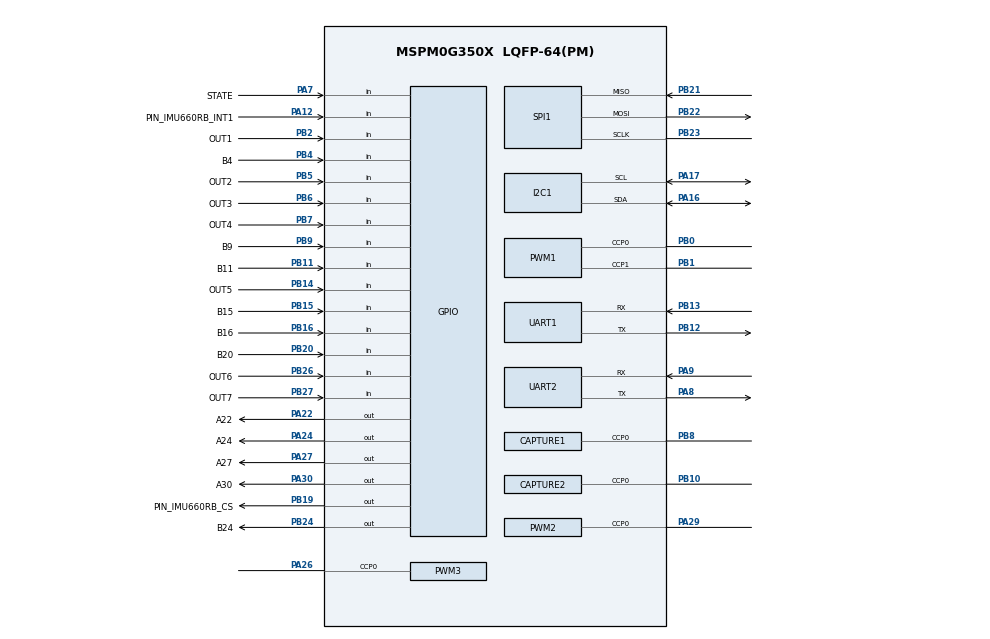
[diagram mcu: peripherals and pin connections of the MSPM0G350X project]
/**
 * @cliArgs --device "MSPM0G350X" --part "Default" --package "LQFP-64(PM)" --product "mspm0_sdk@2.05.01.00"
 * @versions {"tool":"1.24.0+4110"}
 */

/**
 * Import the modules used in this configuration.
 */
const CAPTURE  = scripting.addModule("/ti/driverlib/CAPTURE", {}, false);
const CAPTURE1 = CAPTURE.addInstance();
const CAPTURE2 = CAPTURE.addInstance();
const GPIO     = scripting.addModule("/ti/driverlib/GPIO", {}, false);
const GPIO1    = GPIO.addInstance();
const GPIO2    = GPIO.addInstance();
const GPIO3    = GPIO.addInstance();
const GPIO4    = GPIO.addInstance();
const GPIO5    = GPIO.addInstance();
const GPIO6    = GPIO.addInstance();
const GPIO7    = GPIO.addInstance();
const I2C      = scripting.addModule("/ti/driverlib/I2C", {}, false);
const I2C1     = I2C.addInstance();
const PWM      = scripting.addModule("/ti/driverlib/PWM", {}, false);
const PWM1     = PWM.addInstance();
const PWM2     = PWM.addInstance();
const PWM3     = PWM.addInstance();
const SPI      = scripting.addModule("/ti/driverlib/SPI", {}, false);
const SPI1     = SPI.addInstance();
const SYSCTL   = scripting.addModule("/ti/driverlib/SYSCTL");
const TIMER    = scripting.addModule("/ti/driverlib/TIMER", {}, false);
const TIMER1   = TIMER.addInstance();
const UART     = scripting.addModule("/ti/driverlib/UART", {}, false);
const UART1    = UART.addInstance();
const UART2    = UART.addInstance();

/**
 * Write custom configuration values to the imported modules.
 */
const divider7       = system.clockTree["PLL_PDIV"];
divider7.divideValue = 2;

const divider9       = system.clockTree["UDIV"];
divider9.divideValue = 2;

const multiplier2         = system.clockTree["PLL_QDIV"];
multiplier2.multiplyValue = 5;

const mux8       = system.clockTree["HSCLKMUX"];
mux8.inputSelect = "HSCLKMUX_SYSPLL2X";

CAPTURE1.$name                              = "CAPTURE_encoderl";
CAPTURE1.timerClkDiv                        = 2;
CAPTURE1.captMode                           = "COMBINED";
CAPTURE1.timerClkPrescale                   = 40;
CAPTURE1.timerPeriod                        = "65.536ms";
CAPTURE1.interrupts                         = ["CC0_DN"];
CAPTURE1.interruptPriority                  = "1";
CAPTURE1.peripheral.$assign                 = "TIMA0";
CAPTURE1.peripheral.ccp0Pin.$assign         = "PB8";
CAPTURE1.ccp0PinConfig.hideOutputInversion  = scripting.forceWrite(false);
CAPTURE1.ccp0PinConfig.onlyInternalResistor = scripting.forceWrite(false);
CAPTURE1.ccp0PinConfig.passedPeripheralType = scripting.forceWrite("Digital");
CAPTURE1.ccp0PinConfig.$name                = "ti_driverlib_gpio_GPIOPinGeneric10";

const Board = scripting.addModule("/ti/driverlib/Board", {}, false);

CAPTURE2.$name                              = "CAPTURE_encoderr";
CAPTURE2.captMode                           = "COMBINED";
CAPTURE2.timerClkPrescale                   = 40;
CAPTURE2.timerPeriod                        = "65.536ms";
CAPTURE2.interrupts                         = ["CC0_DN"];
CAPTURE2.interruptPriority                  = "1";
CAPTURE2.peripheral.$assign                 = "TIMG8";
CAPTURE2.peripheral.ccp0Pin.$assign         = "PB10";
CAPTURE2.ccp0PinConfig.hideOutputInversion  = scripting.forceWrite(false);
CAPTURE2.ccp0PinConfig.onlyInternalResistor = scripting.forceWrite(false);
CAPTURE2.ccp0PinConfig.passedPeripheralType = scripting.forceWrite("Digital");
CAPTURE2.ccp0PinConfig.$name                = "ti_driverlib_gpio_GPIOPinGeneric11";

GPIO1.$name                               = "KEY";
GPIO1.associatedPins.create(4);
GPIO1.associatedPins[0].$name             = "B4";
GPIO1.associatedPins[0].direction         = "INPUT";
GPIO1.associatedPins[0].internalResistor  = "PULL_UP";
GPIO1.associatedPins[0].interruptEn       = true;
GPIO1.associatedPins[0].interruptPriority = "3";
GPIO1.associatedPins[0].polarity          = "FALL";
GPIO1.associatedPins[0].pin.$assign       = "PB4";
GPIO1.associatedPins[1].$name             = "B15";
GPIO1.associatedPins[1].direction         = "INPUT";
GPIO1.associatedPins[1].internalResistor  = "PULL_UP";
GPIO1.associatedPins[1].interruptEn       = true;
GPIO1.associatedPins[1].polarity          = "FALL";
GPIO1.associatedPins[1].interruptPriority = "3";
GPIO1.associatedPins[1].pin.$assign       = "PB15";
GPIO1.associatedPins[2].$name             = "B16";
GPIO1.associatedPins[2].direction         = "INPUT";
GPIO1.associatedPins[2].internalResistor  = "PULL_UP";
GPIO1.associatedPins[2].interruptEn       = true;
GPIO1.associatedPins[2].interruptPriority = "3";
GPIO1.associatedPins[2].polarity          = "FALL";
GPIO1.associatedPins[2].pin.$assign       = "PB16";
GPIO1.associatedPins[3].$name             = "B20";
GPIO1.associatedPins[3].direction         = "INPUT";
GPIO1.associatedPins[3].internalResistor  = "PULL_UP";
GPIO1.associatedPins[3].interruptEn       = true;
GPIO1.associatedPins[3].interruptPriority = "3";
GPIO1.associatedPins[3].polarity          = "FALL";
GPIO1.associatedPins[3].pin.$assign       = "PB20";

GPIO2.$name                              = "GPIO_trace";
GPIO2.port                               = "PORTB";
GPIO2.associatedPins.create(7);
GPIO2.associatedPins[0].direction        = "INPUT";
GPIO2.associatedPins[0].internalResistor = "PULL_UP";
GPIO2.associatedPins[0].$name            = "OUT1";
GPIO2.associatedPins[0].pin.$assign      = "PB2";
GPIO2.associatedPins[1].$name            = "OUT2";
GPIO2.associatedPins[1].direction        = "INPUT";
GPIO2.associatedPins[1].internalResistor = "PULL_UP";
GPIO2.associatedPins[1].pin.$assign      = "PB5";
GPIO2.associatedPins[2].$name            = "OUT3";
GPIO2.associatedPins[2].direction        = "INPUT";
GPIO2.associatedPins[2].internalResistor = "PULL_UP";
GPIO2.associatedPins[2].pin.$assign      = "PB6";
GPIO2.associatedPins[3].$name            = "OUT4";
GPIO2.associatedPins[3].direction        = "INPUT";
GPIO2.associatedPins[3].internalResistor = "PULL_UP";
GPIO2.associatedPins[3].pin.$assign      = "PB7";
GPIO2.associatedPins[4].$name            = "OUT5";
GPIO2.associatedPins[4].direction        = "INPUT";
GPIO2.associatedPins[4].internalResistor = "PULL_UP";
GPIO2.associatedPins[4].pin.$assign      = "PB14";
GPIO2.associatedPins[5].$name            = "OUT6";
GPIO2.associatedPins[5].direction        = "INPUT";
GPIO2.associatedPins[5].internalResistor = "PULL_UP";
GPIO2.associatedPins[5].pin.$assign      = "PB26";
GPIO2.associatedPins[6].$name            = "OUT7";
GPIO2.associatedPins[6].direction        = "INPUT";
GPIO2.associatedPins[6].internalResistor = "PULL_UP";
GPIO2.associatedPins[6].pin.$assign      = "PB27";

GPIO3.$name                          = "GPIO_Motor";
GPIO3.associatedPins.create(4);
GPIO3.associatedPins[0].$name        = "A24";
GPIO3.associatedPins[0].assignedPort = "PORTA";
GPIO3.associatedPins[0].assignedPin  = "24";
GPIO3.associatedPins[0].pin.$assign  = "PA24";
GPIO3.associatedPins[1].$name        = "A22";
GPIO3.associatedPins[1].assignedPin  = "22";
GPIO3.associatedPins[1].assignedPort = "PORTA";
GPIO3.associatedPins[1].pin.$assign  = "PA22";
GPIO3.associatedPins[2].$name        = "A30";
GPIO3.associatedPins[2].assignedPort = "PORTA";
GPIO3.associatedPins[2].assignedPin  = "30";
GPIO3.associatedPins[2].pin.$assign  = "PA30";
GPIO3.associatedPins[3].$name        = "B24";
GPIO3.associatedPins[3].assignedPort = "PORTB";
GPIO3.associatedPins[3].assignedPin  = "24";
GPIO3.associatedPins[3].pin.$assign  = "PB24";

GPIO4.$name                               = "GPIO_encoder";
GPIO4.associatedPins.create(2);
GPIO4.associatedPins[0].$name             = "B11";
GPIO4.associatedPins[0].direction         = "INPUT";
GPIO4.associatedPins[0].interruptPriority = "0";
GPIO4.associatedPins[0].polarity          = "RISE";
GPIO4.associatedPins[0].assignedPort      = "PORTB";
GPIO4.associatedPins[0].pin.$assign       = "PB11";
GPIO4.associatedPins[1].$name             = "B9";
GPIO4.associatedPins[1].direction         = "INPUT";
GPIO4.associatedPins[1].pin.$assign       = "PB9";

GPIO5.$name                         = "HC05";
GPIO5.associatedPins[0].$name       = "STATE";
GPIO5.associatedPins[0].direction   = "INPUT";
GPIO5.associatedPins[0].pin.$assign = "PA7";

GPIO6.$name                         = "beep";
GPIO6.associatedPins[0].$name       = "A27";
GPIO6.associatedPins[0].pin.$assign = "PA27";

GPIO7.$name                                 = "GPIO_IMU660RB";
GPIO7.associatedPins.create(2);
GPIO7.associatedPins[0].ioStructure         = "SD";
GPIO7.associatedPins[0].$name               = "PIN_IMU660RB_CS";
GPIO7.associatedPins[0].pin.$assign         = "PB19";
GPIO7.associatedPins[1].$name               = "PIN_IMU660RB_INT1";
GPIO7.associatedPins[1].direction           = "INPUT";
GPIO7.associatedPins[1].interruptEn         = true;
GPIO7.associatedPins[1].polarity            = "FALL";
GPIO7.associatedPins[1].assignedPortSegment = "Lower";
GPIO7.associatedPins[1].interruptPriority   = "1";
GPIO7.associatedPins[1].pin.$assign         = "PA12";

I2C1.$name                             = "I2C_OLED";
I2C1.basicEnableController             = true;
I2C1.basicControllerStandardBusSpeed   = "Fast";
I2C1.peripheral.$assign                = "I2C1";
I2C1.peripheral.sdaPin.$assign         = "PA16";
I2C1.peripheral.sclPin.$assign         = "PA17";
I2C1.sdaPinConfig.hideOutputInversion  = scripting.forceWrite(false);
I2C1.sdaPinConfig.onlyInternalResistor = scripting.forceWrite(false);
I2C1.sdaPinConfig.passedPeripheralType = scripting.forceWrite("Digital");
I2C1.sdaPinConfig.$name                = "ti_driverlib_gpio_GPIOPinGeneric0";
I2C1.sclPinConfig.hideOutputInversion  = scripting.forceWrite(false);
I2C1.sclPinConfig.onlyInternalResistor = scripting.forceWrite(false);
I2C1.sclPinConfig.passedPeripheralType = scripting.forceWrite("Digital");
I2C1.sclPinConfig.$name                = "ti_driverlib_gpio_GPIOPinGeneric1";

PWM1.$name                              = "PWM_Motor";
PWM1.timerCount                         = 8000;
PWM1.timerStartTimer                    = true;
PWM1.pwmMode                            = "EDGE_ALIGN_UP";
PWM1.peripheral.ccp0Pin.$assign         = "PB0";
PWM1.peripheral.ccp1Pin.$assign         = "PB1";
PWM1.PWM_CHANNEL_0.$name                = "ti_driverlib_pwm_PWMTimerCC1";
PWM1.PWM_CHANNEL_1.$name                = "ti_driverlib_pwm_PWMTimerCC2";
PWM1.ccp0PinConfig.direction            = scripting.forceWrite("OUTPUT");
PWM1.ccp0PinConfig.hideOutputInversion  = scripting.forceWrite(false);
PWM1.ccp0PinConfig.onlyInternalResistor = scripting.forceWrite(false);
PWM1.ccp0PinConfig.passedPeripheralType = scripting.forceWrite("Digital");
PWM1.ccp0PinConfig.$name                = "ti_driverlib_gpio_GPIOPinGeneric8";
PWM1.ccp1PinConfig.direction            = scripting.forceWrite("OUTPUT");
PWM1.ccp1PinConfig.hideOutputInversion  = scripting.forceWrite(false);
PWM1.ccp1PinConfig.onlyInternalResistor = scripting.forceWrite(false);
PWM1.ccp1PinConfig.passedPeripheralType = scripting.forceWrite("Digital");
PWM1.ccp1PinConfig.$name                = "ti_driverlib_gpio_GPIOPinGeneric9";

PWM2.clockDivider                       = 8;
PWM2.ccIndex                            = [0];
PWM2.clockPrescale                      = 10;
PWM2.timerCount                         = 20000;
PWM2.pwmMode                            = "EDGE_ALIGN_UP";
PWM2.timerStartTimer                    = true;
PWM2.$name                              = "servo_1";
PWM2.PWM_CHANNEL_0.$name                = "ti_driverlib_pwm_PWMTimerCC3";
PWM2.ccp0PinConfig.direction            = scripting.forceWrite("OUTPUT");
PWM2.ccp0PinConfig.hideOutputInversion  = scripting.forceWrite(false);
PWM2.ccp0PinConfig.onlyInternalResistor = scripting.forceWrite(false);
PWM2.ccp0PinConfig.passedPeripheralType = scripting.forceWrite("Digital");
PWM2.ccp0PinConfig.$name                = "ti_driverlib_gpio_GPIOPinGeneric12";
PWM2.peripheral.$assign                 = "TIMG6";
PWM2.peripheral.ccp0Pin.$assign         = "PA29";

PWM3.$name                              = "servo_2";
PWM3.clockDivider                       = 8;
PWM3.clockPrescale                      = 10;
PWM3.timerCount                         = 20000;
PWM3.pwmMode                            = "EDGE_ALIGN_UP";
PWM3.ccIndex                            = [0];
PWM3.timerStartTimer                    = true;
PWM3.PWM_CHANNEL_0.$name                = "ti_driverlib_pwm_PWMTimerCC0";
PWM3.ccp0PinConfig.direction            = scripting.forceWrite("OUTPUT");
PWM3.ccp0PinConfig.hideOutputInversion  = scripting.forceWrite(false);
PWM3.ccp0PinConfig.onlyInternalResistor = scripting.forceWrite(false);
PWM3.ccp0PinConfig.passedPeripheralType = scripting.forceWrite("Digital");
PWM3.ccp0PinConfig.$name                = "ti_driverlib_gpio_GPIOPinGeneric2";
PWM3.peripheral.$assign                 = "TIMG7";
PWM3.peripheral.ccp0Pin.$assign         = "PA26";

SPI1.frameFormat                        = "MOTO3";
SPI1.$name                              = "SPI_IMU660RB";
SPI1.sclkPinConfig.direction            = scripting.forceWrite("OUTPUT");
SPI1.sclkPinConfig.onlyInternalResistor = scripting.forceWrite(false);
SPI1.sclkPinConfig.passedPeripheralType = scripting.forceWrite("Digital");
SPI1.sclkPinConfig.$name                = "ti_driverlib_gpio_GPIOPinGeneric13";
SPI1.mosiPinConfig.direction            = scripting.forceWrite("OUTPUT");
SPI1.mosiPinConfig.hideOutputInversion  = scripting.forceWrite(false);
SPI1.mosiPinConfig.onlyInternalResistor = scripting.forceWrite(false);
SPI1.mosiPinConfig.passedPeripheralType = scripting.forceWrite("Digital");
SPI1.mosiPinConfig.$name                = "ti_driverlib_gpio_GPIOPinGeneric14";
SPI1.misoPinConfig.onlyInternalResistor = scripting.forceWrite(false);
SPI1.misoPinConfig.passedPeripheralType = scripting.forceWrite("Digital");
SPI1.misoPinConfig.$name                = "ti_driverlib_gpio_GPIOPinGeneric15";
SPI1.peripheral.sclkPin.$assign         = "PB23";
SPI1.peripheral.mosiPin.$assign         = "PB22";
SPI1.peripheral.misoPin.$assign         = "PB21";

SYSCTL.forceDefaultClkConfig = true;
SYSCTL.clockTreeEn           = true;
scripting.suppress("For best practices when the CPUCLK is running at 32MHz and above, clear the flash status bit using DL_FlashCTL_executeClearStatus\\(\\) before executing any flash operation\\. Otherwise there may be false positives\\.", SYSCTL);

TIMER1.$name                            = "TIMER_0";
TIMER1.timerClkDiv                      = 8;
TIMER1.timerMode                        = "PERIODIC";
TIMER1.interrupts                       = ["ZERO"];
TIMER1.timerClkPrescale                 = 50;
TIMER1.interruptPriority                = "0";
TIMER1.timerPeriod                      = "10 ms";
TIMER1.peripheral.$assignAllowConflicts = "TIMG0";

UART1.$name                            = "HC_05";
UART1.uartClkDiv                       = "4";
UART1.enabledInterrupts                = ["RX"];
UART1.targetBaudRate                   = 115200;
UART1.interruptPriority                = "2";
UART1.peripheral.$assign               = "UART3";
UART1.peripheral.rxPin.$assign         = "PB13";
UART1.peripheral.txPin.$assign         = "PB12";
UART1.txPinConfig.direction            = scripting.forceWrite("OUTPUT");
UART1.txPinConfig.hideOutputInversion  = scripting.forceWrite(false);
UART1.txPinConfig.onlyInternalResistor = scripting.forceWrite(false);
UART1.txPinConfig.passedPeripheralType = scripting.forceWrite("Digital");
UART1.txPinConfig.$name                = "ti_driverlib_gpio_GPIOPinGeneric4";
UART1.rxPinConfig.hideOutputInversion  = scripting.forceWrite(false);
UART1.rxPinConfig.onlyInternalResistor = scripting.forceWrite(false);
UART1.rxPinConfig.passedPeripheralType = scripting.forceWrite("Digital");
UART1.rxPinConfig.$name                = "ti_driverlib_gpio_GPIOPinGeneric5";

UART2.$name                            = "UART_0";
UART2.uartClkDiv                       = "4";
UART2.targetBaudRate                   = 115200;
UART2.enabledInterrupts                = ["RX"];
UART2.peripheral.rxPin.$assign         = "PA9";
UART2.peripheral.txPin.$assign         = "PA8";
UART2.txPinConfig.direction            = scripting.forceWrite("OUTPUT");
UART2.txPinConfig.hideOutputInversion  = scripting.forceWrite(false);
UART2.txPinConfig.onlyInternalResistor = scripting.forceWrite(false);
UART2.txPinConfig.passedPeripheralType = scripting.forceWrite("Digital");
UART2.txPinConfig.$name                = "ti_driverlib_gpio_GPIOPinGeneric6";
UART2.rxPinConfig.hideOutputInversion  = scripting.forceWrite(false);
UART2.rxPinConfig.onlyInternalResistor = scripting.forceWrite(false);
UART2.rxPinConfig.passedPeripheralType = scripting.forceWrite("Digital");
UART2.rxPinConfig.$name                = "ti_driverlib_gpio_GPIOPinGeneric7";

/**
 * Pinmux solution for unlocked pins/peripherals. This ensures that minor changes to the automatic solver in a future
 * version of the tool will not impact the pinmux you originally saw.  These lines can be completely deleted in order to
 * re-solve from scratch.
 */
Board.peripheral.$suggestSolution          = "DEBUGSS";
Board.peripheral.swclkPin.$suggestSolution = "PA20";
Board.peripheral.swdioPin.$suggestSolution = "PA19";
PWM1.peripheral.$suggestSolution           = "TIMA1";
SPI1.peripheral.$suggestSolution           = "SPI1";
UART2.peripheral.$suggestSolution          = "UART1";
